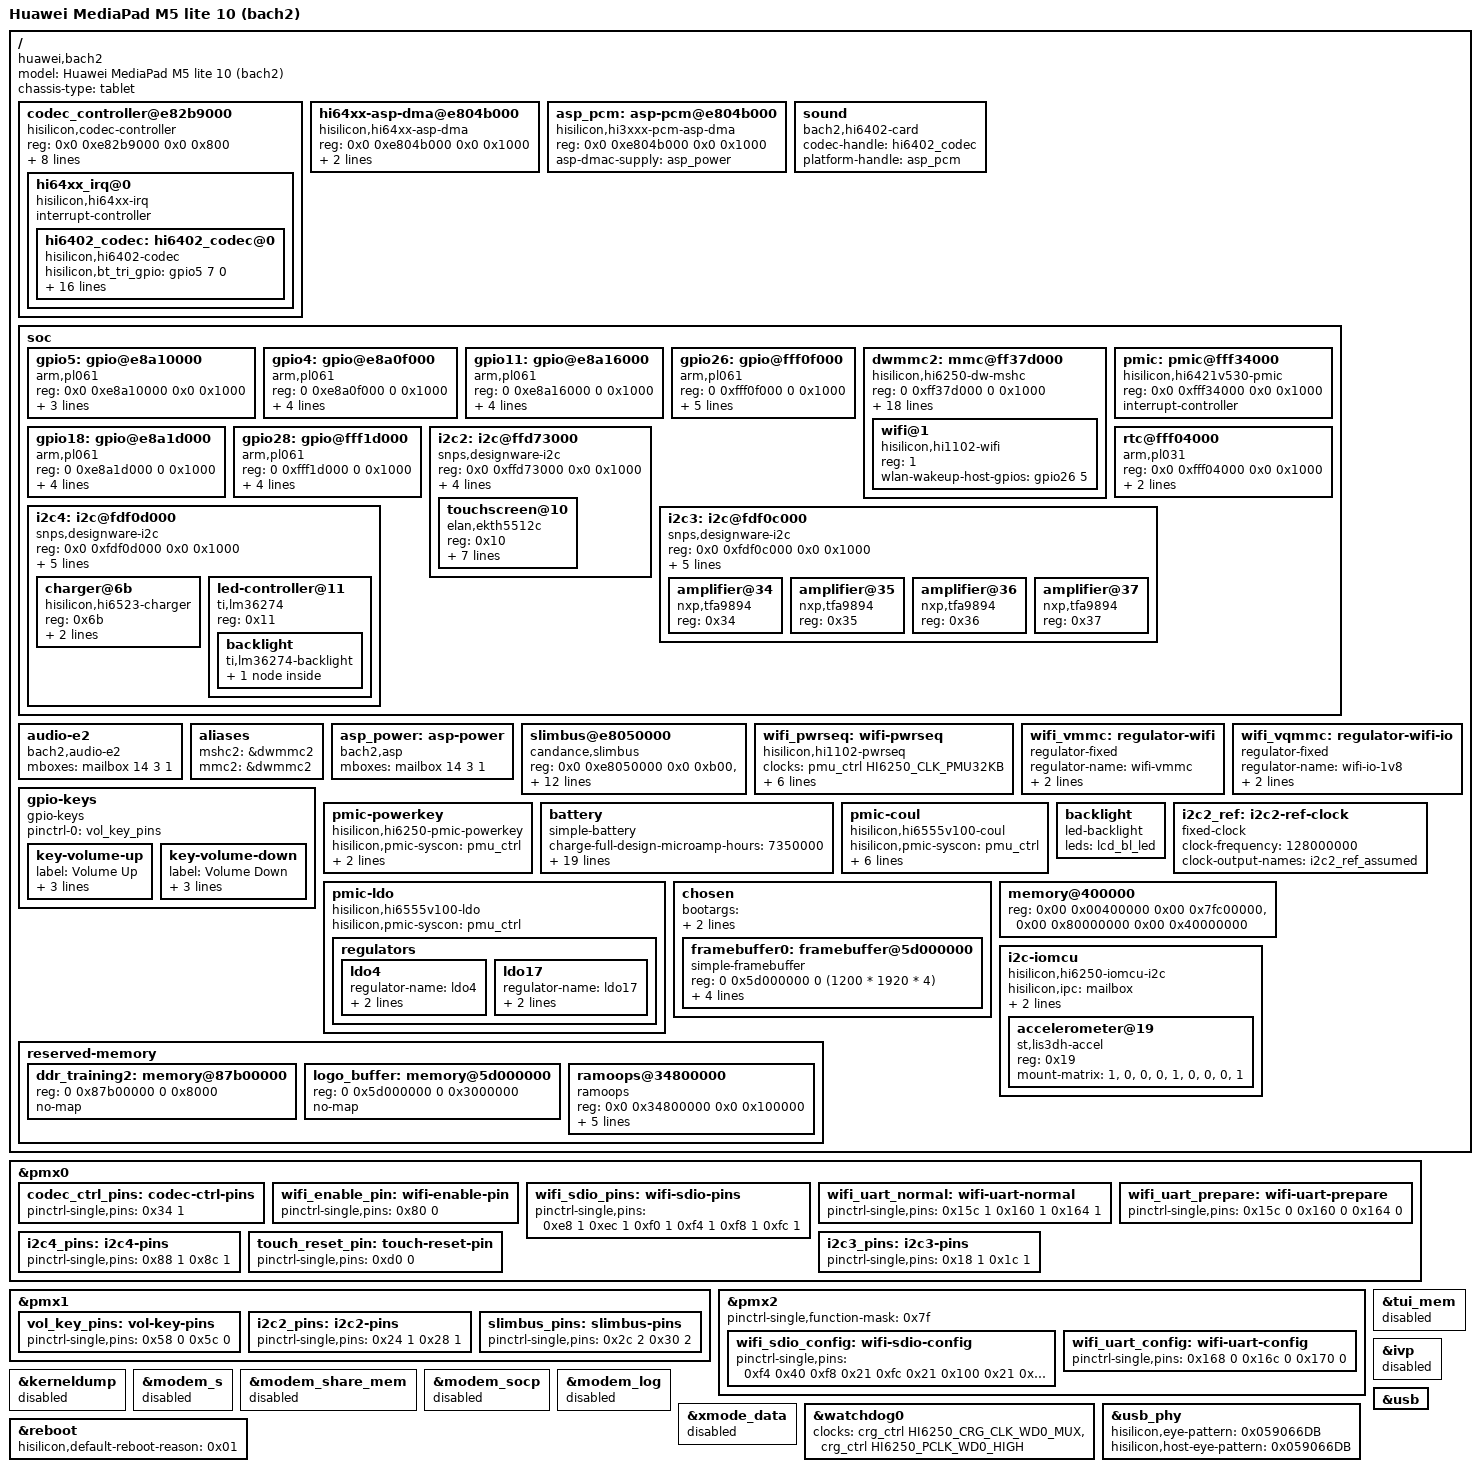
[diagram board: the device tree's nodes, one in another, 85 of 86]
// SPDX-License-Identifier: GPL-2.0-only
/*
 * Huawei MediaPad M5 lite 10 (BAH2-W19, "bach2"). Bring-up DT, derived from hi6250-huawei-agassi2.dts.
 * Booted through the bach2 boot shim (the bootloader's DTB is replaced, so nothing here is fixed up by it).
 */
/dts-v1/;

#include "hi6250.dtsi"
#include <dt-bindings/input/input.h>

/*
 * Audio codec + DSP-free PCM (proposed 0052, docs/mainline-audio-port.md). Needs 0051 (asp_power,
 * slimbus) and 0006 (gpio26). Inert without the out-of-tree modules hi_cdc_ctrl, hi64xx_irq,
 * hi6402_codec, hi64xx_asp_dma, hi3xxx_asp_pcm and bach2_card: no in-tree driver matches these
 * compatibles. Copied from the stock DT (codec_controller@e82b9000, hi64xx_asp_dmac@E804B000,
 * asp_dmac@E804B000, sound) with mainline phandles.
 */
/ {
	codec_controller@e82b9000 {
		compatible = "hisilicon,codec-controller";
		reg = <0x0 0xe82b9000 0x0 0x800>;
		/* stock gpios = <&gpio@fff0f000 1 0>: the codec interrupt line */
		gpios = <&gpio26 1 0>;
		hisilicon,bus-sel = "slimbus";
		hisilicon,codec-sel = "hi6402";
		hisilicon,reg-8bit-begin-addr = <0x20007000>;
		hisilicon,reg-8bit-end-addr = <0x20007fff>;
		clocks = <&asp_power 0>;
		clock-names = "clk_pmuaudioclk";
		/* stock pinctrl default and idle: gpio016 function 1 */
		pinctrl-names = "default", "idle";
		pinctrl-0 = <&codec_ctrl_pins>;
		pinctrl-1 = <&codec_ctrl_pins>;

		hi64xx_irq@0 {
			compatible = "hisilicon,hi64xx-irq";
			interrupt-controller;
			#interrupt-cells = <2>;

			hi6402_codec: hi6402_codec@0 {
				compatible = "hisilicon,hi6402-codec";
				/* stock <&gpio@e8a10000 7 0> = GPIO 47; the codec drives it to BT_TRI_PA at probe */
				hisilicon,bt_tri_gpio = <&gpio5 7 0>;
				hi6402-soundtrigger-if-4smartpa;
				use_stereo_smartpa = <1>;
				hisilicon,mic_num = <2>;
				hisilicon,hs_det = <0>;
				hisilicon,hs_ctrl = <0x19>;
				hisilicon,coefficient = <0xaf0>;
				hisilicon,hs_3_pole_min_voltage = <0x0>;
				hisilicon,hs_3_pole_max_voltage = <0x8>;
				hisilicon,hs_4_pole_min_voltage = <0x384>;
				hisilicon,hs_4_pole_max_voltage = <0xa5a>;
				hisilicon,btn_play_min_voltage = <0x0>;
				hisilicon,btn_play_max_voltage = <0x64>;
				hisilicon,btn_volume_up_min_voltage = <0x82>;
				hisilicon,btn_volume_up_max_voltage = <0x140>;
				hisilicon,btn_volume_down_min_voltage = <0x140>;
				hisilicon,btn_volume_down_max_voltage = <0x2bc>;
			};
		};
	};

	/* vendor drivers/hisi/hi64xx/asp_dma.c: ASP DMAC channel API (AP interrupt group 0) */
	hi64xx-asp-dma@e804b000 {
		compatible = "hisilicon,hi64xx-asp-dma";
		reg = <0x0 0xe804b000 0x0 0x1000>;
		interrupts = <GIC_SPI 216 IRQ_TYPE_LEVEL_HIGH>;
		interrupt-names = "asp_dma_irq";
		asp-dmac-supply = <&asp_power>;
	};

	/* vendor sound/soc/hisilicon/hi3xxx_asp_dma.c: PCM into SLIMbus port FIFOs, no HiFi DSP */
	asp_pcm: asp-pcm@e804b000 {
		compatible = "hisilicon,hi3xxx-pcm-asp-dma";
		reg = <0x0 0xe804b000 0x0 0x1000>;
		asp-dmac-supply = <&asp_power>;
	};

	sound {
		compatible = "bach2,hi6402-card";
		codec-handle = <&hi6402_codec>;
		platform-handle = <&asp_pcm>;
	};

	soc {
		/*
		 * GPIO bank 5 (stock gpio@e8a10000, SPI 89 per the stock DT), for the codec's bt_tri_gpio.
		 * Its pclk_gpio5 gate (CRG PEREN1 bit 5) has no mainline clock and reads on (E1:
		 * PERCLKEN1 = PERSTAT1 = 0xffffffff); only the AO APB clock is described.
		 */
		gpio5: gpio@e8a10000 {
			compatible = "arm,pl061", "arm,primecell";
			reg = <0x0 0xe8a10000 0x0 0x1000>;
			interrupts = <GIC_SPI 89 IRQ_TYPE_LEVEL_HIGH>;
			gpio-controller;
			#gpio-cells = <2>;
			clocks = <&ao_ctrl HI6250_APB_PCLK>;
			clock-names = "apb_pclk";
		};
	};
};

&pmx0 {
	/* stock gpio016_pmx_func (pmx0 0x034): function 1, applied to codec_controller */
	codec_ctrl_pins: codec-ctrl-pins {
		pinctrl-single,pins = <0x34 1>;
	};
};

/ {
	model = "Huawei MediaPad M5 lite 10 (bach2)";
	compatible = "huawei,bach2", "hisilicon,hi6250";
	chassis-type = "tablet";

	/*
	 * Audio experiment E2 (proposed 0050, docs/mainline-audio.md section 6): the LPM3 mailbox
	 * channel for the ASP power request. Stock mailbox-14 of ipc@e896b000: src_bit 1 (AP),
	 * des_bit 3 (LPM3), the same IPC and unlock key as stub_clock's mailbox 13 (<13 3 0>).
	 * Nothing binds to it unless hi6402_e2.ko is loaded, and that module sends nothing by default.
	 */
	audio-e2 {
		compatible = "bach2,audio-e2";
		mboxes = <&mailbox 14 3 1>;
	};

	aliases {
		/* dw_mmc-k3 uses mshc, independently of the MMC core's mmc alias. */
		mshc2 = &dwmmc2;
		mmc2 = &dwmmc2;
	};

	/*
	 * Audio (proposed 0051, docs/mainline-audio.md section 7). Inert unless bach2_asp.ko and
	 * hi6402_slimbus.ko are loaded. bach2_asp: the stock "asp" power regulator (LPM3 mailbox 14
	 * {0x50001}/{0x50101}) and the clocks clk_pmuaudioclk (PMIC 0x114 bit 0) and clk_asp_subsys
	 * (LPM3 {0xd0002, 0xb}). Stock DT: asp regulator hi3xxx@15, clk_asp_subsys interactive-clk.
	 */
	asp_power: asp-power {
		compatible = "bach2,asp";
		mboxes = <&mailbox 14 3 1>;
		#clock-cells = <1>;
	};

	/*
	 * Stock slimbusmisc@0xe8050000 (vendor drivers/hisi/slimbus, Cadence CSMI manager; the SoC is
	 * the framer). reg: manager, ASP_CFG, SCTRL (power/clock state words at 0x6c/0x16c).
	 */
	slimbus@e8050000 {
		compatible = "candance,slimbus";
		reg = <0x0 0xe8050000 0x0 0xb00>,
		      <0x0 0xe804e000 0x0 0xa000>,
		      <0x0 0xfff0a000 0x0 0x1000>;
		interrupts = <GIC_SPI 150 IRQ_TYPE_LEVEL_HIGH>;
		interrupt-names = "asp_irq_slimbus";
		clocks = <&asp_power 0>, <&asp_power 1>;
		clock-names = "clk_pmuaudioclk", "clk_asp_subsys";
		slimbus-reg-supply = <&asp_power>;
		pinctrl-names = "default", "idle";
		pinctrl-0 = <&slimbus_pins>;
		pinctrl-1 = <&slimbus_pins>;
		platform-type = "ASIC";
		slimbus-ssi-sel = "slimbus";
		asp_power_state_offset = <0x6c>;
		asp_clk_state_offset = <0x16c>;
		hi6402-soundtrigger-if1-used;
	};

	wifi_pwrseq: wifi-pwrseq {
		compatible = "hisilicon,hi1102-pwrseq";
		clocks = <&pmu_ctrl HI6250_CLK_PMU32KB>;
		clock-names = "ext_clock";
		reset-gpios = <&gpio4 3 GPIO_ACTIVE_LOW>;
		xldo-gpios = <&gpio11 3 GPIO_ACTIVE_HIGH>;
		pinctrl-names = "default", "power-prepare";
		pinctrl-0 = <&wifi_enable_pin &wifi_uart_normal &wifi_uart_config>;
		pinctrl-1 = <&wifi_enable_pin &wifi_uart_prepare &wifi_uart_config>;
	};

	wifi_vmmc: regulator-wifi {
		compatible = "regulator-fixed";
		regulator-name = "wifi-vmmc";
		regulator-min-microvolt = <2800000>;
		regulator-max-microvolt = <2800000>;
	};

	wifi_vqmmc: regulator-wifi-io {
		compatible = "regulator-fixed";
		regulator-name = "wifi-io-1v8";
		regulator-min-microvolt = <1800000>;
		regulator-max-microvolt = <1800000>;
	};

	/*
	 * Volume keys. Stock: hisi_gpio_key, gpio-keyup = GPIO 201, gpio-keydown = GPIO 202
	 * (= gpio25 lines 1, 2), pressed = low (hisi_gpio_key.c), 15 ms debounce timer.
	 */
	gpio-keys {
		compatible = "gpio-keys";
		pinctrl-names = "default";
		pinctrl-0 = <&vol_key_pins>;

		key-volume-up {
			label = "Volume Up";
			linux,code = <KEY_VOLUMEUP>;
			gpios = <&gpio25 1 GPIO_ACTIVE_LOW>;
			debounce-interval = <15>;
		};

		key-volume-down {
			label = "Volume Down";
			linux,code = <KEY_VOLUMEDOWN>;
			gpios = <&gpio25 2 GPIO_ACTIVE_LOW>;
			debounce-interval = <15>;
		};
	};

	/*
	 * Stock ponkey@b1 under hisilicon,hisi-pmic: PMIC IRQ status 0x1b0 bits 7/6 (press/release);
	 * PMIC summary IRQ on gpio23 line 7 (stock gpios = <&gpio@fff0c000 7 0>), level low.
	 */
	pmic-powerkey {
		compatible = "hisilicon,hi6250-pmic-powerkey";
		hisilicon,pmic-syscon = <&pmu_ctrl>;
		interrupts-extended = <&gpio23 7 IRQ_TYPE_LEVEL_LOW>;
	};

	/*
	 * Stock battery (live DT battery profiles desayatl/sunwodaguangyu/scudsony_7350_*_4400, all
	 * identical in these values; this unit's ID 1040 mV selects sunwodaguangyu): fcc 7350 mAh,
	 * vbat_max 4400 mV, coul normal_cutoff_vol_mv 3150. Charge limits from the stock
	 * charging_core node at 5 V input: ichg_ac 2100 mA, iterm 260 mA; hi6523_chip_init()
	 * precharge 200 mA. JEITA (temp_para): no charge below 0 C or above 50 C, 700 mA at 0-5 C,
	 * CV 4100 mV at 40-50 C; coul_core batt_temp_too_cold/too_hot = -20/60 C.
	 * These are descriptive here: the 0070 drivers are read-only and enforce nothing.
	 * ocv-capacity-table-0: sunwodaguangyu pc_temp_ocv_ocv, 25 C column (vendor
	 * hisi_battery_data.c temp_points -20/-10/0/25/40/60; the normal 4.4 V table, not the
	 * aged "_ocv0"). Internal resistance: stock Rbatt 101 mOhm (dmesg RBATT_ADJ).
	 */
	battery: battery {
		compatible = "simple-battery";
		charge-full-design-microamp-hours = <7350000>;
		voltage-max-design-microvolt = <4400000>;
		voltage-min-design-microvolt = <3150000>;
		constant-charge-voltage-max-microvolt = <4400000>;
		constant-charge-current-max-microamp = <2100000>;
		charge-term-current-microamp = <260000>;
		precharge-current-microamp = <200000>;
		operating-range-celsius = <(-20) 60>;
		factory-internal-resistance-micro-ohms = <101000>;
		ocv-capacity-celsius = <25>;
		ocv-capacity-table-0 = <4370000 100>, <4296000 95>, <4238000 90>, <4181000 85>,
			<4127000 80>, <4077000 75>, <4028000 70>, <3983000 65>, <3938000 60>,
			<3889000 55>, <3852000 50>, <3826000 45>, <3806000 40>, <3789000 35>,
			<3774000 30>, <3758000 25>, <3739000 20>, <3714000 15>, <3686000 10>,
			<3685000 9>, <3683000 8>, <3679000 7>, <3674000 6>, <3660000 5>,
			<3623000 4>, <3569000 3>, <3500000 2>, <3391000 1>, <3200000 0>;
	};

	/*
	 * Stock hi6555v100_coul@1 under hisilicon,hisi-pmic (fff34000). Read-only (0070).
	 * charge-full: stock learned FCC of this pack, 6868 mAh (dmesg FCC=6868000uAh).
	 * Trim: the stock in-use values (C0, vendor Linux /sys/class/hw_power/coul/coul_data
	 * pl_v_offset_a/_b, pl_c_offset_a/_b, work/power-C0.txt). Without these properties the
	 * driver falls back to the ATE OTP values (a=1000000, b=-31500 on this unit).
	 */
	pmic-coul {
		compatible = "hisilicon,hi6555v100-coul";
		hisilicon,pmic-syscon = <&pmu_ctrl>;
		monitored-battery = <&battery>;
		hisilicon,charge-full-microamp-hours = <6868000>;
		hisilicon,v-offset-a = <1006021>;
		hisilicon,v-offset-b-microvolt = <(-12752)>;
		hisilicon,c-offset-a = <1000000>;
		hisilicon,c-offset-b-microamp = <0>;
	};

	/* /sys/class/backlight/backlight: starts in the bootloader's state, capped by lcd_bl_led. */
	backlight: backlight {
		compatible = "led-backlight";
		leds = <&lcd_bl_led>;
	};

	/*
	 * Touch I2C (i2c@ffd73000) functional clock. Stock clk_i2c2 = fixed-factor 1:1 of the fixed
	 * clk_fll_src (128 MHz), no gate in the AP clock tree. The vendor DT asks for 19.2 MHz
	 * (clock-rate), which a fixed-factor-of-fixed clock cannot provide, so the vendor timing is
	 * computed for 128 MHz too [I]. If the real rate is lower, SCL only gets slower.
	 */
	i2c2_ref: i2c2-ref-clock {
		compatible = "fixed-clock";
		#clock-cells = <0>;
		clock-frequency = <128000000>;
		clock-output-names = "i2c2_ref_assumed";
	};

	/*
	 * Touch rails (Hi6555v100 PMIC, stock vendor DT ldo@19 / ldo@25). Off after the bootloader
	 * (TOUCH stage A, 2026-11-24: ctrl 0x19 / 0x25 and vset 0x42 / 0x4e all 0). On stock only
	 * elan_ts switches them. The driver (0045) refuses any selector but the stock one, so a
	 * constraint edit here cannot raise them; min == max makes the core program the stock
	 * selector once at registration, while the LDO is still off.
	 */
	pmic-ldo {
		compatible = "hisilicon,hi6555v100-ldo";
		hisilicon,pmic-syscon = <&pmu_ctrl>;

		regulators {
			/* touch VDDIO, stock vddio_ldo_value 1.8 V */
			ldo4: ldo4 {
				regulator-name = "ldo4";
				regulator-min-microvolt = <1800000>;
				regulator-max-microvolt = <1800000>;
			};

			/* touch VCI, stock vci_ldo_value 3.3 V */
			ldo17: ldo17 {
				regulator-name = "ldo17";
				regulator-min-microvolt = <3300000>;
				regulator-max-microvolt = <3300000>;
			};
		};
	};

	chosen {
		bootargs = "console=tty0 loglevel=8 ignore_loglevel printk.time=1";

		#address-cells = <2>;
		#size-cells = <2>;
		ranges;

		stdout-path = "framebuffer0";

		/* The bootloader leaves the DSS scanning out its logo buffer (stock DT: logo-buffer @ 0x5d000000). */
		framebuffer0: framebuffer@5d000000 {
			compatible = "simple-framebuffer";
			reg = <0 0x5d000000 0 (1200 * 1920 * 4)>;
			width = <1200>;
			height = <1920>;
			stride = <(1200 * 4)>;
			format = "a8r8g8b8";
			status = "okay";
		};
	};

	reserved-memory {
		/* Bootloader fills this in at runtime: ddr-training2@0 -> 0x87b00000 (live DT, status ok, no-map);
		 * the vendor kernel's /proc/iomem shows the matching 32 KiB hole. */
		ddr_training2: memory@87b00000 {
			reg = <0 0x87b00000 0 0x8000>;
			no-map;
		};

		logo_buffer: memory@5d000000 {
			reg = <0 0x5d000000 0 0x3000000>;
			no-map;
		};

		/* Same region and layout as the stock kernel (pstore-mem 0x34800000, 1 MiB),
		 * so the vendor kernel can read this kernel's console after a reboot. */
		ramoops@34800000 {
			compatible = "ramoops";
			reg = <0x0 0x34800000 0x0 0x100000>;
			record-size = <0x20000>;
			console-size = <0x80000>;
			ftrace-size = <0x0>;
			pmsg-size = <0x20000>;
			ecc-size = <0x0>;
		};
	};

	/* Live DT handed to the vendor kernel (/proc/device-tree, 2026-11-23): two banks split at 2 GiB */
	memory@400000 {
		device_type = "memory";
		reg = <0x00 0x00400000 0x00 0x7fc00000>,
		      <0x00 0x80000000 0x00 0x40000000>;
	};

	soc {
		gpio4: gpio@e8a0f000 {
			compatible = "arm,pl061", "arm,primecell";
			reg = <0 0xe8a0f000 0 0x1000>;
			interrupts = <GIC_SPI 88 IRQ_TYPE_LEVEL_HIGH>;
			gpio-controller;
			#gpio-cells = <2>;
			clocks = <&crg_ctrl HI6250_PCLK_GPIO4>, <&ao_ctrl HI6250_APB_PCLK>;
			clock-names = "pclk_gpio4", "apb_pclk";
		};

		gpio11: gpio@e8a16000 {
			compatible = "arm,pl061", "arm,primecell";
			reg = <0 0xe8a16000 0 0x1000>;
			interrupts = <GIC_SPI 95 IRQ_TYPE_LEVEL_HIGH>;
			gpio-controller;
			#gpio-cells = <2>;
			clocks = <&crg_ctrl HI6250_PCLK_GPIO11>, <&ao_ctrl HI6250_APB_PCLK>;
			clock-names = "pclk_gpio11", "apb_pclk";
		};

		/* AO GPIO block 4 (stock: gpio@fff0f000, gpio-ranges pmx1 28..35). */
		gpio26: gpio@fff0f000 {
			compatible = "arm,pl061", "arm,primecell";
			reg = <0 0xfff0f000 0 0x1000>;
			interrupts = <GIC_SPI 110 IRQ_TYPE_LEVEL_HIGH>;
			gpio-controller;
			#gpio-cells = <2>;
			interrupt-controller;
			#interrupt-cells = <2>;
			clocks = <&sys_ctrl HI6250_PCLK_AO_GPIO4>, <&ao_ctrl HI6250_APB_PCLK>;
			clock-names = "pclk_ao_gpio4", "apb_pclk";
		};

		dwmmc2: mmc@ff37d000 {
			compatible = "hisilicon,hi6250-dw-mshc";
			reg = <0 0xff37d000 0 0x1000>;
			interrupts = <GIC_SPI 140 IRQ_TYPE_LEVEL_HIGH>;
			clocks = <&crg_ctrl HI6250_CLK_SDIO0>, <&crg_ctrl HI6250_HCLK_SDIO0>;
			clock-names = "ciu", "biu";
			resets = <&crg_rst 0x90 19>;
			reset-names = "reset";
			pinctrl-names = "default";
			pinctrl-0 = <&wifi_sdio_pins &wifi_sdio_config>;
			mmc-pwrseq = <&wifi_pwrseq>;
			vmmc-supply = <&wifi_vmmc>;
			vqmmc-supply = <&wifi_vqmmc>;
			bus-width = <4>;
			/*
			 * Stage B: UHS SDR104 at 160 MHz, as stock (CMD11 to 1.8 V,
			 * timing 6, 160 MHz, tuned). Needs dw_mmc-k3 patch 0007: ciu
			 * ppll0 1440 MHz / (8 + 1). The 1.8 V switch is CMD11 only;
			 * neither stock nor mainline drives any pad-voltage control on
			 * mmc2 (docs/sdio-clock.md). SDR104 only: a SDR50 fallback here
			 * would ask 100 MHz, above the stock SDR50 rate (66.9 MHz).
			 */
			max-frequency = <160000000>;
			cap-sd-highspeed;
			sd-uhs-sdr104;
			fifo-depth = <0x100>;
			non-removable;
			no-mmc;
			no-sd;
			cap-sdio-irq;
			keep-power-in-suspend;
			#address-cells = <1>;
			#size-cells = <0>;
			status = "okay";

			/*
			 * SDIO function 1 of Hi1102 (0296:5347). Read by the vendor
			 * plat.ko board layer (platform/board/board.c), not bound as a
			 * device. Stock: hisi_wifi { hi1102,gpio_wlan_wakeup_host =
			 * <&gpio@fff0f000 5 0>; }, rising-edge device->host wake/data IRQ.
			 */
			wifi@1 {
				compatible = "hisilicon,hi1102-wifi";
				reg = <1>;
				wlan-wakeup-host-gpios = <&gpio26 5 GPIO_ACTIVE_HIGH>;
			};
		};

		pmic: pmic@fff34000 {
			compatible = "hisilicon,hi6421v530-pmic";
			reg = <0x0 0xfff34000 0x0 0x1000>;
			interrupt-controller;
			#interrupt-cells = <2>;
		};

		/*
		 * Touch reset: GPIO 145 = gpio18 line 1 (stock ts_kit reset_gpio). The block gate is
		 * named apb_pclk (as in hi3660.dtsi) so the AMBA bus enables it (0043).
		 */
		gpio18: gpio@e8a1d000 {
			compatible = "arm,pl061", "arm,primecell";
			reg = <0 0xe8a1d000 0 0x1000>;
			interrupts = <GIC_SPI 102 IRQ_TYPE_LEVEL_HIGH>;
			gpio-controller;
			#gpio-cells = <2>;
			interrupt-controller;
			#interrupt-cells = <2>;
			clocks = <&crg_ctrl HI6250_PCLK_GPIO18>;
			clock-names = "apb_pclk";
		};

		/* Touch IRQ: gpio28 line 0 (stock ts_kit irq_gpio). */
		gpio28: gpio@fff1d000 {
			compatible = "arm,pl061", "arm,primecell";
			reg = <0 0xfff1d000 0 0x1000>;
			interrupts = <GIC_SPI 162 IRQ_TYPE_LEVEL_HIGH>;
			gpio-controller;
			#gpio-cells = <2>;
			interrupt-controller;
			#interrupt-cells = <2>;
			clocks = <&sys_ctrl HI6250_PCLK_AO_GPIO6>;
			clock-names = "apb_pclk";
		};

		/*
		 * Stock i2c@FFD73000 (alias i2c2; i2c-0 on the vendor kernel [I]): hisi DesignWare in the
		 * IOMCU domain, SPI 120, 400 kHz on stock (no speed-mode). The vendor driver writes no
		 * clock gate; it pulses the IOMCU reset (0xffd7e000 + 0x20/0x24, status 0x28, bit 5) at
		 * probe. Neither is modelled here: the bootloader state is used [I: the stock kernel
		 * reads this block at 26.4 s, before the IOMCU reports ready at 27.7 s]. 100 kHz.
		 */
		i2c2: i2c@ffd73000 {
			compatible = "snps,designware-i2c";
			reg = <0x0 0xffd73000 0x0 0x1000>;
			interrupts = <GIC_SPI 120 IRQ_TYPE_LEVEL_HIGH>;
			clocks = <&i2c2_ref>;
			clock-frequency = <100000>;
			pinctrl-names = "default";
			pinctrl-0 = <&i2c2_pins>;
			#address-cells = <1>;
			#size-cells = <0>;

			/*
			 * Stock: ts_kit + elan_ts (drivers/devkit/tpkit/panel/elan, CONFIG_ELAN_TS_KIT=y; not the
			 * unbuilt tpkit/3_0 copy), ekth5512c at 0x10. Its commands are HID-over-I2C output reports
			 * (wOutputRegister 0x0004, report ID 3); the HID descriptor address 0x0001 is the
			 * upstream Elan value [I]; the TOUCH diag checks it.
			 * Power and reset, stock elan_ktf_chip_detect(): VCI = ldo17 set to 3.3 V and enabled,
			 * then VDDIO = ldo4 set to 1.8 V and enabled, msleep(1), reset high 5 ms, low 10 ms,
			 * high, msleep(300). i2c-hid-of-elan with the ekth6a12nay timing: reset held low,
			 * vcc33 then vccio enabled in that order, 10 ms, reset released, 300 ms. Same order,
			 * same voltages (locked in the hi6555v100-ldo driver), same >= 10 ms low pulse after power.
			 * IRQ: ts_kit irq_config 0 = TS_IRQ_LOW_LEVEL.
			 */
			touchscreen@10 {
				compatible = "elan,ekth5512c", "elan,ekth6a12nay";
				reg = <0x10>;
				interrupts-extended = <&gpio28 0 IRQ_TYPE_LEVEL_LOW>;
				reset-gpios = <&gpio18 1 GPIO_ACTIVE_LOW>;
				vcc33-supply = <&ldo17>;
				vccio-supply = <&ldo4>;
				pinctrl-names = "default";
				pinctrl-0 = <&touch_reset_pin>;
				/*
				 * Touch resume T-R1 (docs/mainline-suspend.md): after i2c-hid's suspend power-down (rails
				 * off, reset asserted) the ekth5512c never answers again (controller timed out, every
				 * IOMCU/pad/DW/LDO register unchanged). As a wakeup source, i2c-hid keeps it powered in
				 * SLEEP over suspend instead, as the stock driver does, and a touch can wake the tablet.
				 */
				wakeup-source;
			};
		};

		/*
		 * Stock i2c@FDF0D000 (alias i2c4; i2c-2 on the vendor kernel): DesignWare, SPI 82, clock
		 * clk_i2c4 (CRG 0x20 bit 27), reset CRG 0x78/0x7c bit 27. 100 kHz against an assumed
		 * 120 MHz ref (clk-hi6250.c): SCL is never faster than requested unless the real ref
		 * exceeds 120 MHz.
		 */
		i2c4: i2c@fdf0d000 {
			compatible = "snps,designware-i2c";
			reg = <0x0 0xfdf0d000 0x0 0x1000>;
			interrupts = <GIC_SPI 82 IRQ_TYPE_LEVEL_HIGH>;
			clocks = <&crg_ctrl HI6250_CLK_I2C4>;
			resets = <&crg_rst 0x78 27>;
			clock-frequency = <100000>;
			pinctrl-names = "default";
			pinctrl-0 = <&i2c4_pins>;
			#address-cells = <1>;
			#size-cells = <0>;

			/*
			 * Stock hi6523_charger@6B (huawei,hi6523_charger, status ok; the bq2560x/hi6522/
			 * rt9466 alternatives at 0x6b are disabled). Chip id register 0x04 = 1..3.
			 * Read-only (0070): no IRQ (stock gpio_int = ao gpio22 line 4, not modelled).
			 */
			charger@6b {
				compatible = "hisilicon,hi6523-charger";
				reg = <0x6b>;
				monitored-battery = <&battery>;
				/* P2 managed charging (docs/mainline-power.md): CV 4100 mV, 700 mA, IIN 1000 mA, 40 s HW watchdog */
				hisilicon,managed-charging;
			};

			/*
			 * Stock: huawei,hw_ktz8864 / huawei,hw_lm36274 @0x11, run by lcdkit's common
			 * backlight-IC driver as "hw_lm36274" (huawei,lcd_panel lcd-bl-ic-name).
			 * Brightness: 11 bits, 0x04[2:0] (LSB) + 0x05 (MSB); stock enable 0x08 = 0x1f.
			 * Linux writes only BL_EN (when it differs from 0x1f) and the brightness registers.
			 * LCD bias (0x09-0x0e) and current settings (0x02/0x03/0x10/0x11) stay as the
			 * bootloader left them: there is no regulators node and REGULATOR_LM363X is off.
			 */
			led-controller@11 {
				compatible = "ti,lm36274";
				reg = <0x11>;

				backlight {
					compatible = "ti,lm36274-backlight";

					lcd_bl_led: led {
						label = "white:backlight";
						led-sources = <0 1 2 3>;
						/*
						 * Stock ceiling: hisifb blmax 7582 (hw,lcdkit-panel-blmax
						 * = 0x1d9e) -> bl_lvl_map() -> code 1958 of 2047. Stock
						 * everyday hisifb level 3032 -> code 1657.
						 */
						max-brightness = <1958>;
					};
				};
			};
		};
	};
};

&pmx0 {
	wifi_enable_pin: wifi-enable-pin {
		pinctrl-single,pins = <0x80 0>;
	};
	wifi_sdio_pins: wifi-sdio-pins {
		pinctrl-single,pins = <0xe8 1 0xec 1 0xf0 1 0xf4 1 0xf8 1 0xfc 1>;
	};
	wifi_uart_normal: wifi-uart-normal {
		pinctrl-single,pins = <0x15c 1 0x160 1 0x164 1>;
	};
	wifi_uart_prepare: wifi-uart-prepare {
		pinctrl-single,pins = <0x15c 0 0x160 0 0x164 0>;
	};
};

/* Inputs and backlight */
&pmx0 {
	/* Stock gpio037/gpio038_pmx_func: function 1 = I2C4 SCL/SDA */
	i2c4_pins: i2c4-pins {
		pinctrl-single,pins = <0x88 1 0x8c 1>;
	};
};

&pmx1 {
	/* Stock gpio201/gpio202_pmx_func: function 0 = GPIO */
	vol_key_pins: vol-key-pins {
		pinctrl-single,pins = <0x58 0 0x5c 0>;
	};
};

/* Touch */
&pmx0 {
	/* Stock gpio055_pmx_func (gpio18 gpio-ranges: line 1 = pin 52): function 0 = GPIO */
	touch_reset_pin: touch-reset-pin {
		pinctrl-single,pins = <0xd0 0>;
	};
};

&pmx1 {
	/* Stock gpio187/gpio188_pmx_func of i2c@FFD73000: function 1 = I2C2 SCL/SDA */
	i2c2_pins: i2c2-pins {
		pinctrl-single,pins = <0x24 1 0x28 1>;
	};
};

&pmx2 {
	status = "okay";
	pinctrl-single,function-mask = <0x7f>;
	wifi_sdio_config: wifi-sdio-config {
		/* Stock: CLK 8 mA/no pull, CMD + DAT[3:0] 4 mA/pull-up. */
		pinctrl-single,pins = <0xf4 0x40 0xf8 0x21 0xfc 0x21
				      0x100 0x21 0x104 0x21 0x108 0x21>;
	};
	wifi_uart_config: wifi-uart-config {
		pinctrl-single,pins = <0x168 0 0x16c 0 0x170 0>;
	};
};

/* status = "disabled" in the live DT of this wifi-only board (BAH2-W19): not reserved there */
&kerneldump { status = "disabled"; };
&tui_mem { status = "disabled"; };

&pmx1 {
	/* Stock gpio189/gpio190_pmx_func (pmx1 0x02c/0x030): function 2 = SLIMbus clock/data */
	slimbus_pins: slimbus-pins {
		pinctrl-single,pins = <0x2c 2 0x30 2>;
	};
};

&ivp { status = "disabled"; };
&modem_s { status = "disabled"; };
&modem_share_mem { status = "disabled"; };
&modem_socp { status = "disabled"; };
&modem_log { status = "disabled"; };
&xmode_data { status = "disabled"; };

/*
 * SP805 (watchdog@e8a06000). Counter clock: clk_wd0_mux (CRG 0x140 bit 17: clkin_ref 32764 Hz or
 * pclk_wd0_high), as in the live vendor DT, so WDTLOAD follows the source the bootloader selected.
 * Bus clock: pclk_wd0_high (CRG gate 0x20 bit 16, named as the block's APB clock) instead of the
 * fixed apb_pclk, so the gate is held even when the counter runs from clkin_ref. Needs proposed/0090.
 */
&watchdog0 {
	clocks = <&crg_ctrl HI6250_CRG_CLK_WD0_MUX>, <&crg_ctrl HI6250_PCLK_WD0_HIGH>;
	clock-names = "wdog_clk", "apb_pclk";
};

&usb_phy {
	status = "ok";
	/* agassi2 values; bach2 stock values not yet extracted */
	hisilicon,eye-pattern = <0x059066DB>;
	hisilicon,host-eye-pattern = <0x059066DB>;
};

&usb {
	status = "ok";
};

/* Bring-up: every plain reboot or panic goes to fastboot (vendor reason 0x01), so the host can restore the stock kernel. */
&reboot {
	hisilicon,default-reboot-reason = <0x01>;
};

/*
 * Speaker amplifiers: bus only (proposed 0060/0061, docs/mainline-amps.md).
 * Stock i2c@FDF0C000 (alias i2c3; i2c-1 on the vendor kernel): DesignWare, SPI 81, clock clk_i2c3
 * (CRG 0x20 bit 7), reset CRG 0x78/0x7c bit 7, vendor clock-rate 120 MHz, pins gpio009/gpio010.
 * Stock children: 4x TFA9894 at 0x34-0x37 (smartpakit chip_id 1, 2, 3, 0). They are deliberately
 * not described: nothing in this kernel binds to them, and AMP_DIAG only reads them from userspace.
 * Amp reset (GPIO 58) and IRQs (GPIO 194-197, secure gpio24 bank) are not described either.
 */
&{/soc} {
	i2c3: i2c@fdf0c000 {
		compatible = "snps,designware-i2c";
		reg = <0x0 0xfdf0c000 0x0 0x1000>;
		interrupts = <GIC_SPI 81 IRQ_TYPE_LEVEL_HIGH>;
		clocks = <&crg_ctrl HI6250_CLK_I2C3>;
		resets = <&crg_rst 0x78 7>;
		clock-frequency = <100000>;
		pinctrl-names = "default";
		pinctrl-0 = <&i2c3_pins>;
		#address-cells = <1>;
		#size-cells = <0>;

		/*
		 * 4x TFA9894 (proposed 0062). Bound only by the out-of-tree tfa98xx-bach2.ko (BACH2_TFA builds);
		 * no in-tree driver matches "nxp,tfa9894". Reset GPIO 58 reads low at boot (A1), so it is not described.
		 */
		/* stock smartpakit chip_id 1, container device 'R' (right-up), TDM slot 1 */
		amplifier@34 {
			compatible = "nxp,tfa9894";
			reg = <0x34>;
		};

		/* stock smartpakit chip_id 2, container device 'LT' (left-down), TDM slot 0 */
		amplifier@35 {
			compatible = "nxp,tfa9894";
			reg = <0x35>;
		};

		/* stock smartpakit chip_id 3, container device 'RQ' (right-down), TDM slot 1 */
		amplifier@36 {
			compatible = "nxp,tfa9894";
			reg = <0x36>;
		};

		/* stock smartpakit chip_id 0, container device 'L' (left-up), TDM slot 0 */
		amplifier@37 {
			compatible = "nxp,tfa9894";
			reg = <0x37>;
		};
	};
};

&pmx0 {
	/* Stock gpio009/gpio010_pmx_func (pmx0 0x018/0x01c): function 1 = I2C3 */
	i2c3_pins: i2c3-pins {
		pinctrl-single,pins = <0x18 1 0x1c 1>;
	};
};

/*
 * SoC RTC (proposed 0130, docs/mainline-suspend.md): stock DT "soc_rtc" (hisilicon,soc-rtc) at 0xfff04000,
 * GIC SPI 46 [V live DT]. Its PrimeCell IDs read 31 10 04 00 0d f0 05 b1, an ARM PL031 [V power survey,
 * self-cycle 20261125-150339-49e14f], found stopped (CR=0). rtc-pl031 sets CR.EN at probe. It is the wake
 * alarm for s2idle; mainline has no driver for the PMIC RTC that stock uses. apb_pclk: the AO APB clock,
 * as for the AO GPIO blocks.
 */
/ {
	soc {
		rtc@fff04000 {
			compatible = "arm,pl031", "arm,primecell";
			reg = <0x0 0xfff04000 0x0 0x1000>;
			interrupts = <GIC_SPI 46 IRQ_TYPE_LEVEL_HIGH>;
			clocks = <&ao_ctrl HI6250_APB_PCLK>;
			clock-names = "apb_pclk";
		};
	};
};

/*
 * IOMCU sensorhub I2C relay (proposed 0140/0141, docs/mainline-sensorhub.md S3). Stock fastboot loads the
 * IOMCU firmware (partition "sensorhub", into sensorhub_s) and leaves it waiting [V S1]. The driver writes
 * the CONFIG_ON_DDR page (last 4 KiB of sensorhub_share_mem), sends STARTUP on IPC mailbox 10, waits for
 * MINI ready on mailbox 4 (stock mailbox-4: SPI 201 [V live DT]; polled as well) and relays I2C transfers
 * to the firmware's I2C0, the sensor bus [V S2: AK09918 @0x0c, LIS3DH @0x19]. The IPC block stays the
 * hi3660-mbox node's; the driver maps only mailboxes 4/10 and the lock register.
 */
/ {
	i2c-iomcu {
		compatible = "hisilicon,hi6250-iomcu-i2c";
		hisilicon,ipc = <&mailbox>;
		interrupts = <GIC_SPI 201 IRQ_TYPE_LEVEL_HIGH>;
		memory-region = <&sensorhub_share_mem>;
		#address-cells = <1>;
		#size-cells = <0>;

		/*
		 * Stock sensorhub gsensor acc2 (huawei,st-lis3dh, WHO_AM_I 0x33 [V S2]). No interrupts (stock
		 * gpio_int1/2 are IOMCU-side GPIOs; sysfs raw reads poll), no supplies (sensor-io = PMIC ldo24,
		 * on from boot [V S2], not described). mount-matrix: stock axis_map 0/1/2, negate 0/0/0, so the
		 * chip frame is the Android frame of the panel [I]; flat face-up reads z = +976 mg [V S2], so
		 * z is right; the x/y signs are [I] until an upright reading confirms them. The AK09918
		 * magnetometer @0x0c is not described.
		 */
		accelerometer@19 {
			compatible = "st,lis3dh-accel";
			reg = <0x19>;
			mount-matrix = "1", "0", "0",
				       "0", "1", "0",
				       "0", "0", "1";
		};
	};
};
#include "hi6250-huawei-bach2-emmc.dtsi"
